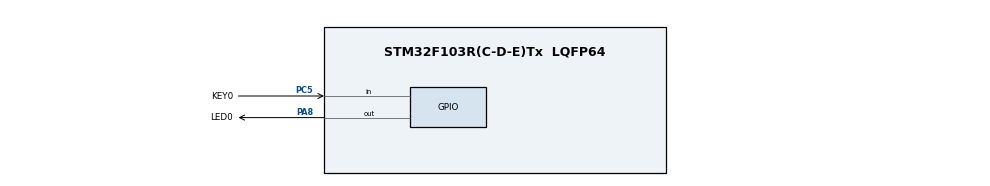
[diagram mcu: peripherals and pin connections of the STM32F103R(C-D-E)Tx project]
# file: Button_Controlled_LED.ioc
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Mcu.Family=STM32F1
Mcu.Name=STM32F103R(C-D-E)Tx
Mcu.Package=LQFP64
NVIC.PriorityGroup=NVIC_PRIORITYGROUP_4
PA13.Mode=JTAG_5_pins
PA13.Signal=SYS_JTMS-SWDIO
PA14.Mode=JTAG_5_pins
PA14.Signal=SYS_JTCK-SWCLK
PA15.Mode=JTAG_5_pins
PA15.Signal=SYS_JTDI
PA8.GPIO_Label=LED0
PA8.GPIO_ModeDefaultOutputPP=GPIO_MODE_OUTPUT_PP
PA8.GPIO_PuPd=GPIO_NOPULL
PA8.GPIO_Speed=GPIO_SPEED_FREQ_HIGH
PA8.PinState=GPIO_PIN_SET
PA8.Signal=GPIO_Output
PB3.Mode=JTAG_5_pins
PB3.Signal=SYS_JTDO-TRACESWO
PB4.Mode=JTAG_5_pins
PB4.Signal=SYS_NJTRST
PC14-OSC32_IN.Mode=LSE-External-Oscillator
PC14-OSC32_IN.Signal=RCC_OSC32_IN
PC15-OSC32_OUT.Mode=LSE-External-Oscillator
PC15-OSC32_OUT.Signal=RCC_OSC32_OUT
PC5.GPIO_Label=KEY0
PC5.GPIO_PuPd=GPIO_PULLUP
PC5.Signal=GPIO_Input
PD0-OSC_IN.Mode=HSE-External-Oscillator
PD0-OSC_IN.Signal=RCC_OSC_IN
PD1-OSC_OUT.Mode=HSE-External-Oscillator
PD1-OSC_OUT.Signal=RCC_OSC_OUT
ProjectManager.HeapSize=0x200
ProjectManager.StackSize=0x400
ProjectManager.TargetToolchain=STM32CubeIDE
RCC.APB1Freq_Value=8000000
RCC.APB2Freq_Value=8000000
board=custom

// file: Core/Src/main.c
/* USER CODE BEGIN Header */
/**
  ******************************************************************************
  * @file           : main.c
  * @brief          : Main program body
  ******************************************************************************
  * @attention
  *
  * Copyright (c) 2022 STMicroelectronics.
  * All rights reserved.
  *
  * This software is licensed under terms that can be found in the LICENSE file
  * in the root directory of this software component.
  * If no LICENSE file comes with this software, it is provided AS-IS.
  *
  ******************************************************************************
  */
/* USER CODE END Header */
#include "main.h"

void SystemClock_Config(void);
static void MX_GPIO_Init(void);

int main(void)
{

    /* MCU Configuration--------------------------------------------------------*/

    /* Reset of all peripherals, Initializes the Flash interface and the Systick. */
    HAL_Init();

    /* Configure the system clock */
    SystemClock_Config();

    /* Initialize all configured peripherals */
    MX_GPIO_Init();

    /* Infinite loop */
    /* USER CODE BEGIN WHILE */
    while (1)
    {
        if(HAL_GPIO_ReadPin(KEY0_GPIO_Port, KEY0_Pin) == 0 )
        {
            HAL_Delay(100);
            while(HAL_GPIO_ReadPin(KEY0_GPIO_Port, KEY0_Pin) == 0 );
            HAL_Delay(100);
            HAL_GPIO_TogglePin(LED0_GPIO_Port, LED0_Pin);
        }
        /* USER CODE END WHILE */

    }
}

void SystemClock_Config(void)
{
    RCC_OscInitTypeDef RCC_OscInitStruct = {0};
    RCC_ClkInitTypeDef RCC_ClkInitStruct = {0};

    /** Initializes the RCC Oscillators according to the specified parameters
    * in the RCC_OscInitTypeDef structure.
    */
    RCC_OscInitStruct.OscillatorType = RCC_OSCILLATORTYPE_HSI;
    RCC_OscInitStruct.HSIState = RCC_HSI_ON;
    RCC_OscInitStruct.HSICalibrationValue = RCC_HSICALIBRATION_DEFAULT;
    RCC_OscInitStruct.PLL.PLLState = RCC_PLL_NONE;
    if (HAL_RCC_OscConfig(&RCC_OscInitStruct) != HAL_OK)
    {
        Error_Handler();
    }

    /** Initializes the CPU, AHB and APB buses clocks
    */
    RCC_ClkInitStruct.ClockType = RCC_CLOCKTYPE_HCLK|RCC_CLOCKTYPE_SYSCLK
                                  |RCC_CLOCKTYPE_PCLK1|RCC_CLOCKTYPE_PCLK2;
    RCC_ClkInitStruct.SYSCLKSource = RCC_SYSCLKSOURCE_HSI;
    RCC_ClkInitStruct.AHBCLKDivider = RCC_SYSCLK_DIV1;
    RCC_ClkInitStruct.APB1CLKDivider = RCC_HCLK_DIV1;
    RCC_ClkInitStruct.APB2CLKDivider = RCC_HCLK_DIV1;

    if (HAL_RCC_ClockConfig(&RCC_ClkInitStruct, FLASH_LATENCY_0) != HAL_OK)
    {
        Error_Handler();
    }
}

static void MX_GPIO_Init(void)
{
    GPIO_InitTypeDef GPIO_InitStruct = {0};

    /* GPIO Ports Clock Enable */
    __HAL_RCC_GPIOC_CLK_ENABLE();
    __HAL_RCC_GPIOD_CLK_ENABLE();
    __HAL_RCC_GPIOA_CLK_ENABLE();
    __HAL_RCC_GPIOB_CLK_ENABLE();

    /*Configure GPIO pin Output Level */
    HAL_GPIO_WritePin(LED0_GPIO_Port, LED0_Pin, GPIO_PIN_SET);

    /*Configure GPIO pin : KEY0_Pin */
    GPIO_InitStruct.Pin = KEY0_Pin;
    GPIO_InitStruct.Mode = GPIO_MODE_INPUT;
    GPIO_InitStruct.Pull = GPIO_PULLUP;
    HAL_GPIO_Init(KEY0_GPIO_Port, &GPIO_InitStruct);

    /*Configure GPIO pin : LED0_Pin */
    GPIO_InitStruct.Pin = LED0_Pin;
    GPIO_InitStruct.Mode = GPIO_MODE_OUTPUT_OD;
    GPIO_InitStruct.Pull = GPIO_NOPULL;
    GPIO_InitStruct.Speed = GPIO_SPEED_FREQ_HIGH;
    HAL_GPIO_Init(LED0_GPIO_Port, &GPIO_InitStruct);

}

void Error_Handler(void)
{
    __disable_irq();
    while (1)
    {
    }
}
